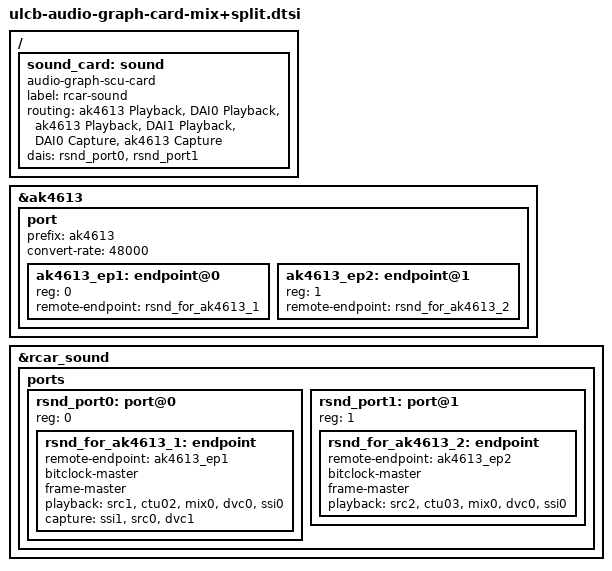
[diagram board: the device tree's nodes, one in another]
/ {
	sound_card: sound {
		compatible = "audio-graph-scu-card";
		label = "rcar-sound";
		routing = "ak4613 Playback", "DAI0 Playback",
			  "ak4613 Playback", "DAI1 Playback",
			  "DAI0 Capture",    "ak4613 Capture";
		dais = <&rsnd_port0  
			&rsnd_port1  
		>;
	};
};
&ak4613 {
	port {
		#address-cells = <1>;
		#size-cells = <0>;
		prefix = "ak4613";
		convert-rate = <48000>;
		ak4613_ep1: endpoint@0 {
			reg = <0>;
			remote-endpoint = <&rsnd_for_ak4613_1>;
		};
		ak4613_ep2: endpoint@1 {
			reg = <1>;
			remote-endpoint = <&rsnd_for_ak4613_2>;
		};
	};
};
&rcar_sound {
	ports {
		#address-cells = <1>;
		#size-cells = <0>;
		rsnd_port0: port@0 {
			reg = <0>;
			rsnd_for_ak4613_1: endpoint {
				remote-endpoint = <&ak4613_ep1>;
				bitclock-master;
				frame-master;
				playback = <&src1 &ctu02 &mix0 &dvc0 &ssi0>;
				capture  = <&ssi1 &src0 &dvc1>;
			};
		};
		rsnd_port1: port@1 {
			reg = <1>;
			rsnd_for_ak4613_2: endpoint {
				remote-endpoint = <&ak4613_ep2>;
				bitclock-master;
				frame-master;
				playback = <&src2 &ctu03 &mix0 &dvc0 &ssi0>;
			};
		};
	};
};
